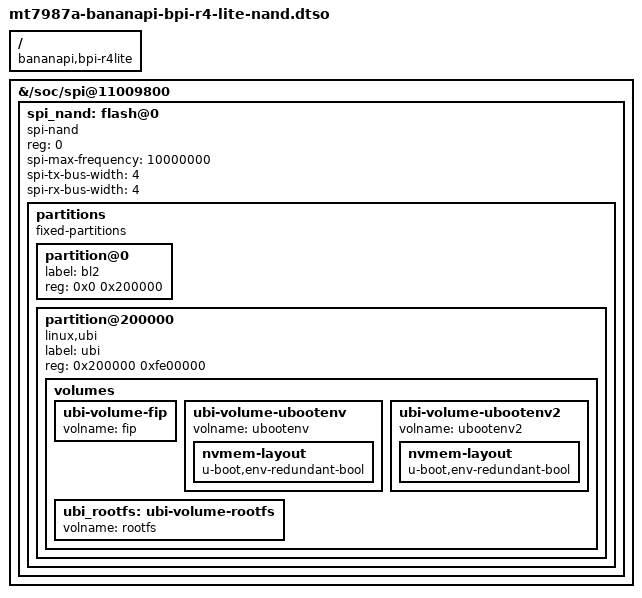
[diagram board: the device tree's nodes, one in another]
/* SPDX-License-Identifier: (GPL-2.0-only OR MIT) */
/*
 * Authors: Daniel Golle <daniel@makrotopia.org>
 *          Frank Wunderlich <frank-w@public-files.de>
 */

/dts-v1/;
/plugin/;

/ {
	compatible = "bananapi,bpi-r4lite", "mediatek,mt7987a";
};

&{/soc/spi@11009800} {
	#address-cells = <1>;
	#size-cells = <0>;
	status = "okay";

	spi_nand: flash@0 {
		compatible = "spi-nand";
		reg = <0>;
		spi-max-frequency = <10000000>;
		spi-tx-bus-width = <4>;
		spi-rx-bus-width = <4>;

		partitions {
			compatible = "fixed-partitions";
			#address-cells = <1>;
			#size-cells = <1>;

			partition@0 {
				label = "bl2";
				reg = <0x0 0x200000>;
			};

			partition@200000 {
				label = "ubi";
				reg = <0x200000 0xfe00000>;
				compatible = "linux,ubi";

				volumes {
					ubi-volume-fip {
						volname = "fip";
					};

					ubi-volume-ubootenv {
						volname = "ubootenv";
						nvmem-layout {
							compatible = "u-boot,env-redundant-bool";
						};
					};

					ubi-volume-ubootenv2 {
						volname = "ubootenv2";
						nvmem-layout {
							compatible = "u-boot,env-redundant-bool";
						};
					};

					ubi_rootfs: ubi-volume-rootfs {
						volname = "rootfs";
					};
				};
			};
		};
	};
};
